# LPC18xx register map
File version: 18
Registers are 32-bit, read-write, reset 0x0 unless marked. A register's access mark holds for its fields unless they carry their own. Offsets are from the block's base; [hi:lo] are bit positions; {n}, {i} and the like mark numbered series; 'fields as' and 'values as' point back to an identical list.

## EMC — Product name title=UM10430 Chapter title=LPC18xx External Memory Controller (EMC) Modification date=1/19/2011 Major revision=0 Minor revision=7
Base 0x40005000
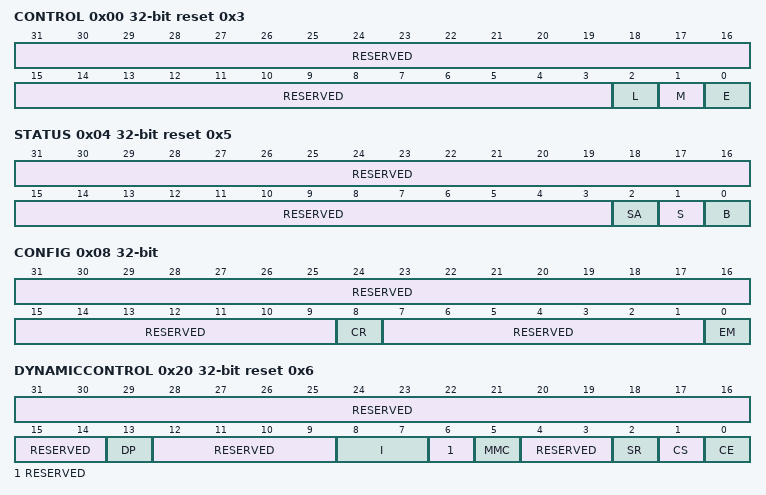
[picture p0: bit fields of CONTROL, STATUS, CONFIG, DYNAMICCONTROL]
0x00 CONTROL reset 0x3 — Controls operation of the memory controller.
  [31:3] RESERVED — Reserved, user software should not write ones to reserved bits. The value read from a reserved bit is not defined.
  [2] L — Low-power mode. Indicates normal, or low-power mode. Entering low-power mode reduces memory controller power consumption. Dynamic memory is refreshed as necessary. The memory controller returns to normal functional mode by clearing the low-power mode bit (L), or by POR. This bit must only be modified when the EMC is in idle state.[1]
    0=NORMAL_MODE_(WARM_RE (Normal mode (warm reset value).); 1=LOW_POWER_MODE_
  [1] M — Address mirror. Indicates normal or reset memory map. On POR, CS1 is mirrored to both CS0 and DYCS0 memory areas. Clearing the M bit enables CS0 and DYCS0 memory to be accessed.
    0=NORMAL_MEMORY_MAP_; 1=RESET_MEMORY_MAP_ST (Reset memory map. Static memory CS1 is mirrored onto CS0 and DYCS0 (POR reset value).)
  [0] E — EMC Enable. Indicates if the EMC is enabled or disabled.Disabling the EMC reduces power consumption. When the memory controller is disabled the memory is not refreshed. The memory controller is enabled by setting the enable bit, or by reset. This bit must only be modified when the EMC is in idle state.[1]
    0=DISABLED; 1=ENABLED_POR_AND_WAR (Enabled (POR and warm reset value).)
0x04 STATUS ro reset 0x5 — Provides EMC status information.
  [31:3] RESERVED — Reserved, user software should not write ones to reserved bits. The value read from a reserved bit is not defined.
  [2] SA — Self-refresh acknowledge. This bit indicates the operating mode of the EMC:
    0=NORMAL_MODE; 1=SELF_REFRESH_MODE_(P (Self-refresh mode (POR reset value).)
  [1] S — Write buffer status. This bit enables the EMC to enter low-power mode or disabled mode cleanly:
    0=WRITE_BUFFERS_EMPTY_ (Write buffers empty (POR reset value)); 1=WRITE_BUFFERS_CONTAI (Write buffers contain data.)
  [0] B — Busy. This bit is used to ensure that the memory controller enters the low-power or disabled mode cleanly by determining if the memory controller is busy or not:
    0=EMC_IS_IDLE_(WARM_RE (EMC is idle (warm reset value).); 1=EMC_IS_BUSY_PERFORMI (EMC is busy performing memory transactions, commands, auto-refresh cycles, or is in self-refresh mode (POR reset value).)
0x08 CONFIG — Configures operation of the memory controller.
  [31:9] RESERVED — Reserved, user software should not write ones to reserved bits. The value read from a reserved bit is not defined.
  [8] CR — Clock Ratio. CCLK: CLKOUT[1:0] ratio:
    0=1TO1_(POR_RESET_VALUE (1:1 (POR reset value)); 1=1TO2 (1:2)
  [7:1] RESERVED — Reserved, user software should not write ones to reserved bits. The value read from a reserved bit is not defined.
  [0] EM — Endian mode.
    0=LITTLE_ENDIAN_MODE_( (Little-endian mode (POR reset value).); 1=BIG_ENDIAN_MODE_
0x20 DYNAMICCONTROL reset 0x6 — Controls dynamic memory operation.
  [31:14] RESERVED — Reserved, user software should not write ones to reserved bits. The value read from a reserved bit is not defined.
  [13] DP — Low-power SDRAM deep-sleep mode.
    0=NORMAL_OPERATION_(PO (Normal operation (POR reset value).); 1=ENTER_DEEP_SLEEP_MOD (Enter Deep-sleep mode.)
  [12:9] RESERVED — Reserved, user software should not write ones to reserved bits. The value read from a reserved bit is not defined.
  [8:7] I — SDRAM initialization.
    0=ISSUE_SDRAM_NORMAL_O (Issue SDRAM NORMAL operation command (POR reset value).); 1=ISSUE_SDRAM_MODE_COM (Issue SDRAM MODE command.); 2=ISSUE_SDRAM_PALL_(PR (Issue SDRAM PALL (precharge all) command.); 3=ISSUE_SDRAM_NOP_(NO_ (Issue SDRAM NOP (no operation) command))
  [6] RESERVED — Reserved, user software should not write ones to reserved bits. The value read from a reserved bit is not defined.
  [5] MMC — Memory clock control.
    0=CLKOUT_ENABLED_(POR_ (CLKOUT enabled (POR reset value).); 1=CLKOUT_DISABLED_[3]
  [4:3] RESERVED — Reserved, user software should not write ones to reserved bits. The value read from a reserved bit is not defined.
  [2] SR — Self-refresh request, EMCSREFREQ. By writing 1 to this bit self-refresh can be entered under software control. Writing 0 to this bit returns the EMC to normal mode. The self-refresh acknowledge bit in the Status register must be polled to discover the current operating mode of the EMC.[2]
    0=NORMAL_MODE_; 1=ENTER_SELF_REFRESH_M (Enter self-refresh mode (POR reset value).)
  [1] CS — Dynamic memory clock control. When clock control is LOW the output clock CLKOUT is stopped when there are no SDRAM transactions. The clock is also stopped during self-refresh mode.
    0=CLKOUT_STOPS_WHEN_AL (CLKOUT stops when all SDRAMs are idle and during self-refresh mode.); 1=CLKOUT_RUNS_CONTINUO (CLKOUT runs continuously (POR reset value).)
  [0] CE — Dynamic memory clock enable.
    0=CLOCK_ENABLE_OF_IDLE (Clock enable of idle devices are deasserted to save power (POR reset value).); 1=ALL_CLOCK_ENABLES_AR (All clock enables are driven HIGH continuously.[1])
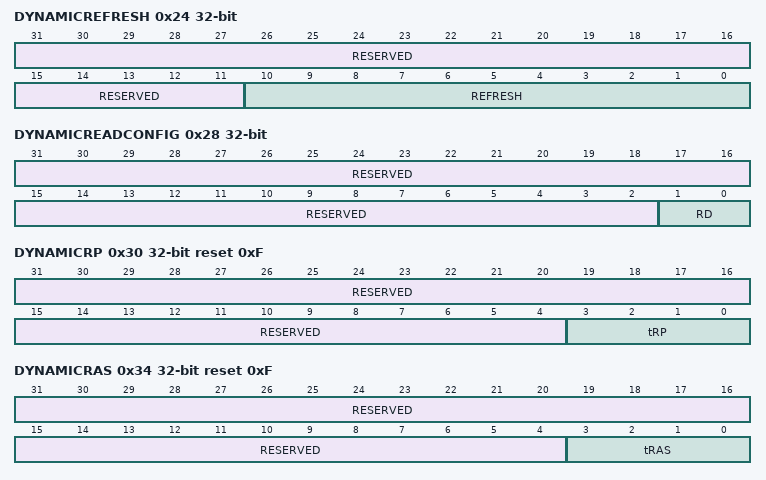
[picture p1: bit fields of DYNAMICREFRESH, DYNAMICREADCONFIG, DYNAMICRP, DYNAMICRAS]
0x24 DYNAMICREFRESH — Configures dynamic memory refresh operation.
  [31:11] RESERVED — Reserved, user software should not write ones to reserved bits. The value read from a reserved bit is not defined.
  [10:0] REFRESH — Refresh timer. Indicates the multiple of 16 CCLKs between SDRAM refresh cycles. 0x0 = Refresh disabled (POR reset value). 0x1 - 0x7FF = n x16 = 16n CCLKs between SDRAM refresh cycles. For example: 0x1 = 1 x 16 = 16 CCLKs between SDRAM refresh cycles. 0x8 = 8 x 16 = 128 CCLKs between SDRAM refresh cycles
0x28 DYNAMICREADCONFIG — Configures the dynamic memory read strategy.
  [31:2] RESERVED — Reserved, user software should not write ones to reserved bits. The value read from a reserved bit is not defined.
  [1:0] RD — Read data strategy.
    0=CLOCK_OUT_DELAYED_ST (Clock out delayed strategy, using CLKOUT (command not delayed, clock out delayed). POR reset value.); 1=COMMAND_DELAYED (Command delayed strategy, using CCLKDELAY (command delayed, clock out not delayed).); 2=COMMAND_DELAYED_PLUS1 (Command delayed strategy plus one clock cycle, using CCLKDELAY (command delayed, clock out not delayed).); 3=COMMAND_DELAYED_PLUS2 (Command delayed strategy plus two clock cycles, using CCLKDELAY (command delayed, clock out not delayed).)
0x30 DYNAMICRP reset 0xF — Selects the precharge command period.
  [31:4] RESERVED — Reserved, user software should not write ones to reserved bits. The value read from a reserved bit is not defined.
  [3:0] tRP — Precharge command period. 0x0 - 0xE = n + 1 clock cycles. The delay is in CCLK cycles. 0xF = 16 clock cycles (POR reset value).
0x34 DYNAMICRAS reset 0xF — Selects the active to precharge command period.
  [31:4] RESERVED — Reserved, user software should not write ones to reserved bits. The value read from a reserved bit is not defined.
  [3:0] tRAS — Active to precharge command period. 0x0 - 0xE = n + 1 clock cycles. The delay is in CCLK cycles. 0xF = 16 clock cycles (POR reset value).
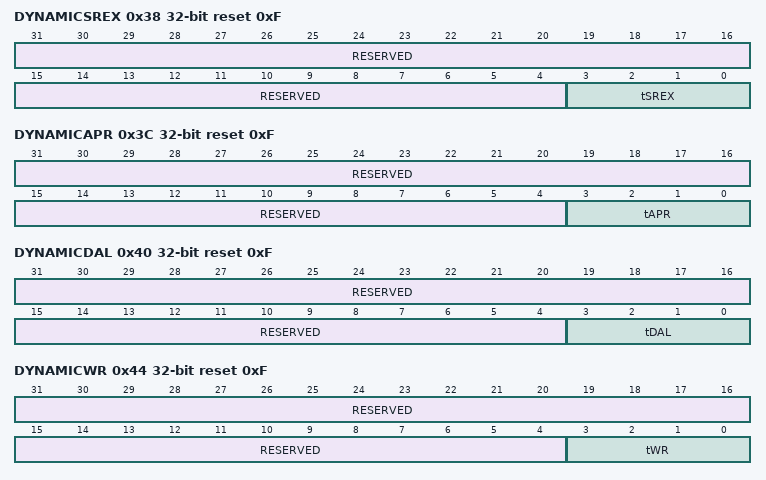
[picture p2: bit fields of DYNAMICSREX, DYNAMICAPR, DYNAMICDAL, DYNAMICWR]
0x38 DYNAMICSREX reset 0xF — Selects the self-refresh exit time.
  [31:4] RESERVED — Reserved, user software should not write ones to reserved bits. The value read from a reserved bit is not defined.
  [3:0] tSREX — Self-refresh exit time . 0x0 - 0xE = n + 1 clock cycles. The delay is in CCLK cycles. 0xF = 16 clock cycles (POR reset value).
0x3C DYNAMICAPR reset 0xF — Selects the last-data-out to active command time.
  [31:4] RESERVED — Reserved, user software should not write ones to reserved bits. The value read from a reserved bit is not defined.
  [3:0] tAPR — Last-data-out to active command time. 0x0 - 0xE = n + 1 clock cycles. The delay is in CCLK cycles. 0xF = 16 clock cycles (POR reset value).
0x40 DYNAMICDAL reset 0xF — Selects the data-in to active command time.
  [31:4] RESERVED — Reserved, user software should not write ones to reserved bits. The value read from a reserved bit is not defined.
  [3:0] tDAL — Data-in to active command. 0x0 - 0xE = n clock cycles. The delay is in CCLK cycles. 0xF = 15 clock cycles (POR reset value).
0x44 DYNAMICWR reset 0xF — Selects the write recovery time.
  [31:4] RESERVED — Reserved, user software should not write ones to reserved bits. The value read from a reserved bit is not defined.
  [3:0] tWR — Write recovery time. 0x0 - 0xE = n + 1 clock cycles. The delay is in CCLK cycles. 0xF = 16 clock cycles (POR reset value).
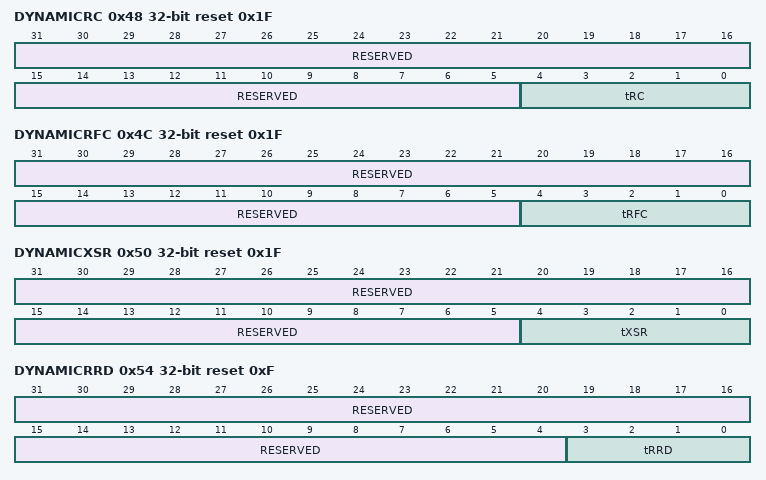
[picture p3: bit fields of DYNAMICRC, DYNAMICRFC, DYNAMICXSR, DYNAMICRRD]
0x48 DYNAMICRC reset 0x1F — Selects the active to active command period.
  [31:5] RESERVED — Reserved, user software should not write ones to reserved bits. The value read from a reserved bit is not defined.
  [4:0] tRC — Active to active command period. 0x0 - 0x1E = n + 1 clock cycles. The delay is in CCLK cycles. 0x1F = 32 clock cycles (POR reset value).
0x4C DYNAMICRFC reset 0x1F — Selects the auto-refresh period.
  [31:5] RESERVED — Reserved, user software should not write ones to reserved bits. The value read from a reserved bit is not defined.
  [4:0] tRFC — Auto-refresh period and auto-refresh to active command period. 0x0 - 0x1E = n + 1 clock cycles. The delay is in CCLK cycles. 0x1F = 32 clock cycles (POR reset value).
0x50 DYNAMICXSR reset 0x1F — Selects the exit self-refresh to active command time.
  [31:5] RESERVED — Reserved, user software should not write ones to reserved bits. The value read from a reserved bit is not defined.
  [4:0] tXSR — Exit self-refresh to active command time. 0x0 - 0x1E = n + 1 clock cycles. The delay is in CCLK cycles. 0x1F = 32 clock cycles (POR reset value).
0x54 DYNAMICRRD reset 0xF — Selects the active bank A to active bank B latency.
  [31:4] RESERVED — Reserved, user software should not write ones to reserved bits. The value read from a reserved bit is not defined.
  [3:0] tRRD — Active bank A to active bank B latency 0x0 - 0xE = n + 1 clock cycles. The delay is in CCLK cycles. 0xF = 16 clock cycles (POR reset value).
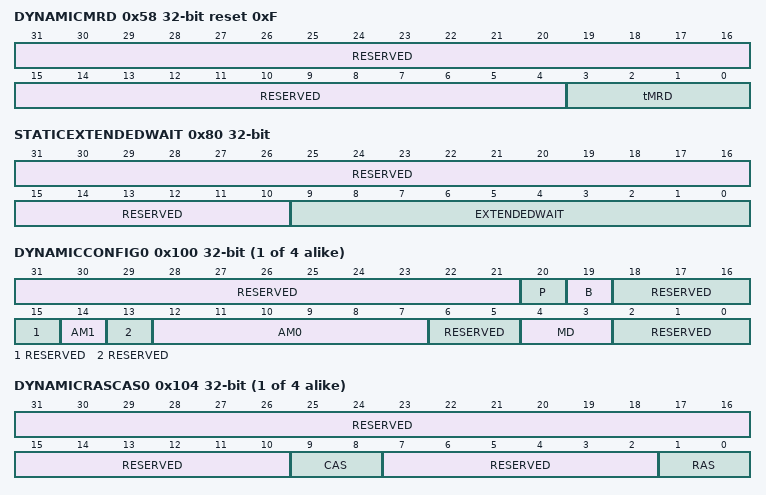
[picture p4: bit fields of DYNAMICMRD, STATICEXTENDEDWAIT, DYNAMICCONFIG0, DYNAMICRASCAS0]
0x58 DYNAMICMRD reset 0xF — Selects the load mode register to active command time.
  [31:4] RESERVED — Reserved, user software should not write ones to reserved bits. The value read from a reserved bit is not defined.
  [3:0] tMRD — Load mode register to active command time. 0x0 - 0xE = n + 1 clock cycles. The delay is in CCLK cycles. 0xF = 16 clock cycles (POR reset value).
0x80 STATICEXTENDEDWAIT — Selects time for long static memory read and write transfers.
  [31:10] RESERVED — Reserved, user software should not write ones to reserved bits. The value read from a reserved bit is not defined.
  [9:0] EXTENDEDWAIT — Extended wait time out. 16 clock cycles (POR reset value). The delay is in CCLK cycles. 0x0 = 16 clock cycles. 0x1 - 0x3FF = (n+1) x16 clock cycles.
{0x100+0x20*i} DYNAMICCONFIG{i} (i=0..3) — Selects the configuration information for dynamic memory chip select n.
  [31:21] RESERVED — Reserved, user software should not write ones to reserved bits. The value read from a reserved bit is not defined.
  [20] P — Write protect.
    0=WRITES_NOT_PROTECTED (Writes not protected (POR reset value).); 1=WRITES_PROTECTED_
  [19] B — Buffer enable.
    0=BUFFER_DISABLED_FOR_ (Buffer disabled for accesses to this chip select (POR reset value).); 1=BUFFER_ENABLED_FOR_A (Buffer enabled for accesses to this chip select. After configuration of the dynamic memory, the buffer must be enabled for normal operation. [2])
  [18:15] RESERVED — Reserved, user software should not write ones to reserved bits. The value read from a reserved bit is not defined.
  [14] AM1 — Address mapping See Table 197. 0 = reset value.
  [13] RESERVED — Reserved, user software should not write ones to reserved bits. The value read from a reserved bit is not defined.
  [12:7] AM0 — Address mapping. See Table 197. 000000 = reset value.[1]
  [6:5] RESERVED — Reserved, user software should not write ones to reserved bits. The value read from a reserved bit is not defined.
  [4:3] MD — Memory device.
    0=SDRAM_(POR_RESET_VAL (SDRAM (POR reset value).); 1=LOW_POWER_SDRAM_; 2=MICRON_SYNCFLASH_
  [2:0] RESERVED — Reserved, user software should not write ones to reserved bits. The value read from a reserved bit is not defined.
{0x104+0x20*i} DYNAMICRASCAS{i} (i=0..3) — Selects the RAS and CAS latencies for dynamic memory chip select n.
  [31:10] RESERVED — Reserved, user software should not write ones to reserved bits. The value read from a reserved bit is not defined.
  [9:8] CAS — CAS latency.
    1=ONE_CCLK_CYCLE_; 2=TWO_CCLK_CYCLES_; 3=THREE_CCLK_CYCLES_(P (Three CCLK cycles (POR reset value).)
  [7:2] RESERVED — Reserved, user software should not write ones to reserved bits. The value read from a reserved bit is not defined.
  [1:0] RAS — RAS latency (active to read/write delay).
    values as CAS
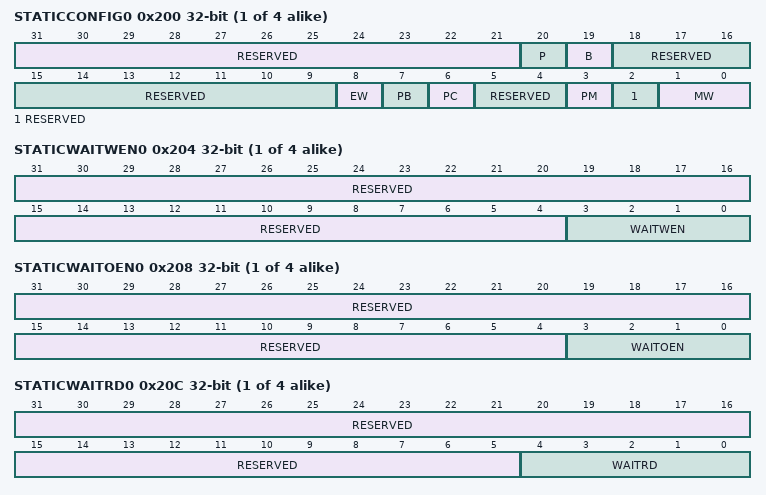
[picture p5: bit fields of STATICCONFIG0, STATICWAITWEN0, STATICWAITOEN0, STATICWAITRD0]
{0x200+0x20*i} STATICCONFIG{i} (i=0..3) — Selects the memory configuration for static chip select n.
  [31:21] RESERVED — Reserved, user software should not write ones to reserved bits. The value read from a reserved bit is not defined.
  [20] P — Write protect.
    0=WRITES_NOT_PROTECTED (Writes not protected (POR reset value).); 1=WRITE_PROTECTED_
  [19] B — Buffer enable[2].
    0=BUFFER_DISABLED_(POR (Buffer disabled (POR reset value).); 1=BUFFER_ENABLED_
  [18:9] RESERVED — Reserved, user software should not write ones to reserved bits. The value read from a reserved bit is not defined.
  [8] EW — Extended wait. Extended wait (EW) uses the StaticExtendedWait register to time both the read and write transfers rather than the StaticWaitRd and StaticWaitWr registers. This enables much longer transactions.[1]
    0=EXTENDED_WAIT_DISABL (Extended wait disabled (POR reset value).); 1=EXTENDED_WAIT_ENABLE (Extended wait enabled.)
  [7] PB — Byte lane state. The byte lane state bit, PB, enables different types of memory to be connected. For byte-wide static memories the BLSn[3:0] signal from the EMC is usually connected to WE (write enable). In this case for reads all the BLSn[3:0] bits must be HIGH. This means that the byte lane state (PB) bit must be LOW. 16 bit wide static memory devices usually have the BLSn[3:0] signals connected to the UBn and LBn (upper byte and lower byte) signals in the static memory. In this case a write to a particular byte must assert the appropriate UBn or LBn signal LOW. For reads, all the UB and LB signals must be asserted LOW so that the bus is driven. In this case the byte lane state (PB) bit must be HIGH. When PB is set to 0, the WE signal is undefined or 0. You must set PB to 1, to use the WE signal.
    0=HIGH (For reads all the bits in BLSn[3:0] are HIGH. For writes the respective active bits in BLSn[3:0] are LOW (POR reset value).); 1=LOW (For reads the respective active bits in BLSn[3:0] are LOW. For writes the respective active bits in BLSn[3:0] are LOW.)
  [6] PC — Chip select polarity. The value of the chip select polarity on power-on reset is 0.
    0=ACTIVE_LOW_CHIP_SELE (Active LOW chip select.); 1=ACTIVE_HIGH_CHIP_SEL (Active HIGH chip select.)
  [5:4] RESERVED — Reserved, user software should not write ones to reserved bits. The value read from a reserved bit is not defined.
  [3] PM — Page mode. In page mode the EMC can burst up to four external accesses. Therefore devices with asynchronous page mode burst four or higher devices are supported. Asynchronous page mode burst two devices are not supported and must be accessed normally.
    0=DISABLED_(POR_RESET_ (Disabled (POR reset value).); 1=ASYNC_PAGE_MODE_ENAB (Async page mode enabled (page length four).)
  [2] RESERVED — Reserved, user software should not write ones to reserved bits. The value read from a reserved bit is not defined.
  [1:0] MW — Memory width.
    0=8_BIT_(POR_RESET_VAL (8 bit (POR reset value).); 1=16_BIT_; 2=32_BIT_
{0x204+0x20*i} STATICWAITWEN{i} (i=0..3) — Selects the delay from chip select n to write enable.
  [31:4] RESERVED — Reserved, user software should not write ones to reserved bits. The value read from a reserved bit is not defined.
  [3:0] WAITWEN — Wait write enable. Delay from chip select assertion to write enable. 0x0 = One CCLK cycle delay between assertion of chip select and write enable (POR reset value). 0x1 - 0xF = (n + 1) CCLK cycle delay. The delay is (WAITWEN +1) x tCCLK.
{0x208+0x20*i} STATICWAITOEN{i} (i=0..3) — Selects the delay from chip select n or address change, whichever is later, to output enable.
  [31:4] RESERVED — Reserved, user software should not write ones to reserved bits. The value read from a reserved bit is not defined.
  [3:0] WAITOEN — Wait output enable. Delay from chip select assertion to output enable. 0x0 = No delay (POR reset value). 0x1 - 0xF = n cycle delay. The delay is WAITOEN x tCCLK.
{0x20C+0x20*i} STATICWAITRD{i} (i=0..3) — Selects the delay from chip select n to a read access.
  [31:5] RESERVED — Reserved, user software should not write ones to reserved bits. The value read from a reserved bit is not defined.
  [4:0] WAITRD — Non-page mode read wait states or asynchronous page mode read first access wait state. Non-page mode read or asynchronous page mode read, first read only: 0x0 - 0x1E = (n + 1) CCLK cycles for read accesses. For non-sequential reads, the wait state time is (WAITRD + 1) x tCCLK. 0x1F = 32 CCLK cycles for read accesses (POR reset value).
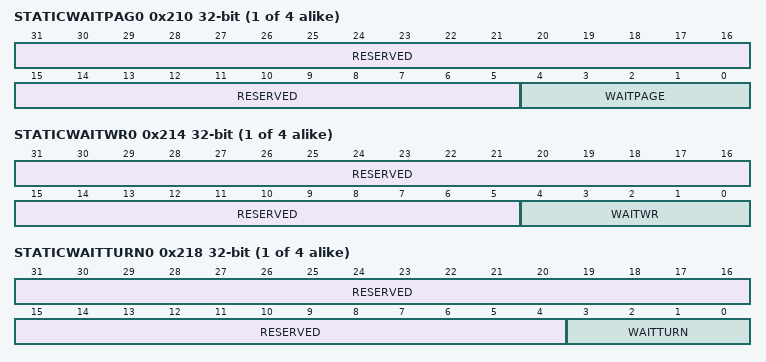
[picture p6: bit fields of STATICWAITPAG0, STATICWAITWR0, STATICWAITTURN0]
{0x210+0x20*i} STATICWAITPAG{i} (i=0..3) — Selects the delay for asynchronous page mode sequential accesses for chip select n.
  [31:5] RESERVED — Reserved, user software should not write ones to reserved bits. The value read from a reserved bit is not defined.
  [4:0] WAITPAGE — Asynchronous page mode read after the first read wait states. Number of wait states for asynchronous page mode read accesses after the first read: 0x0 - 0x1E = (n+ 1) CCLK cycle read access time. For asynchronous page mode read for sequential reads, the wait state time for page mode accesses after the first read is (WAITPAGE + 1) x tCCLK. 0x1F = 32 CCLK cycle read access time (POR reset value).
{0x214+0x20*i} STATICWAITWR{i} (i=0..3) — Selects the delay from chip select n to a write access.
  [31:5] RESERVED — Reserved, user software should not write ones to reserved bits. The value read from a reserved bit is not defined.
  [4:0] WAITWR — Write wait states. SRAM wait state time for write accesses after the first read: 0x0 - 0x1E = (n + 2) CCLK cycle write access time. The wait state time for write accesses after the first read is WAITWR (n + 2) x tCCLK. 0x1F = 33 CCLK cycle write access time (POR reset value).
{0x218+0x20*i} STATICWAITTURN{i} (i=0..3) — Selects bus turnaround cycles
  [31:4] RESERVED — Reserved, user software should not write ones to reserved bits. The value read from a reserved bit is not defined.
  [3:0] WAITTURN — Bus turnaround cycles. 0x0 - 0xE = (n + 1) CCLK turnaround cycles. Bus turnaround time is (WAITTURN + 1) x tCCLK. 0xF = 16 CCLK turnaround cycles (POR reset value).
